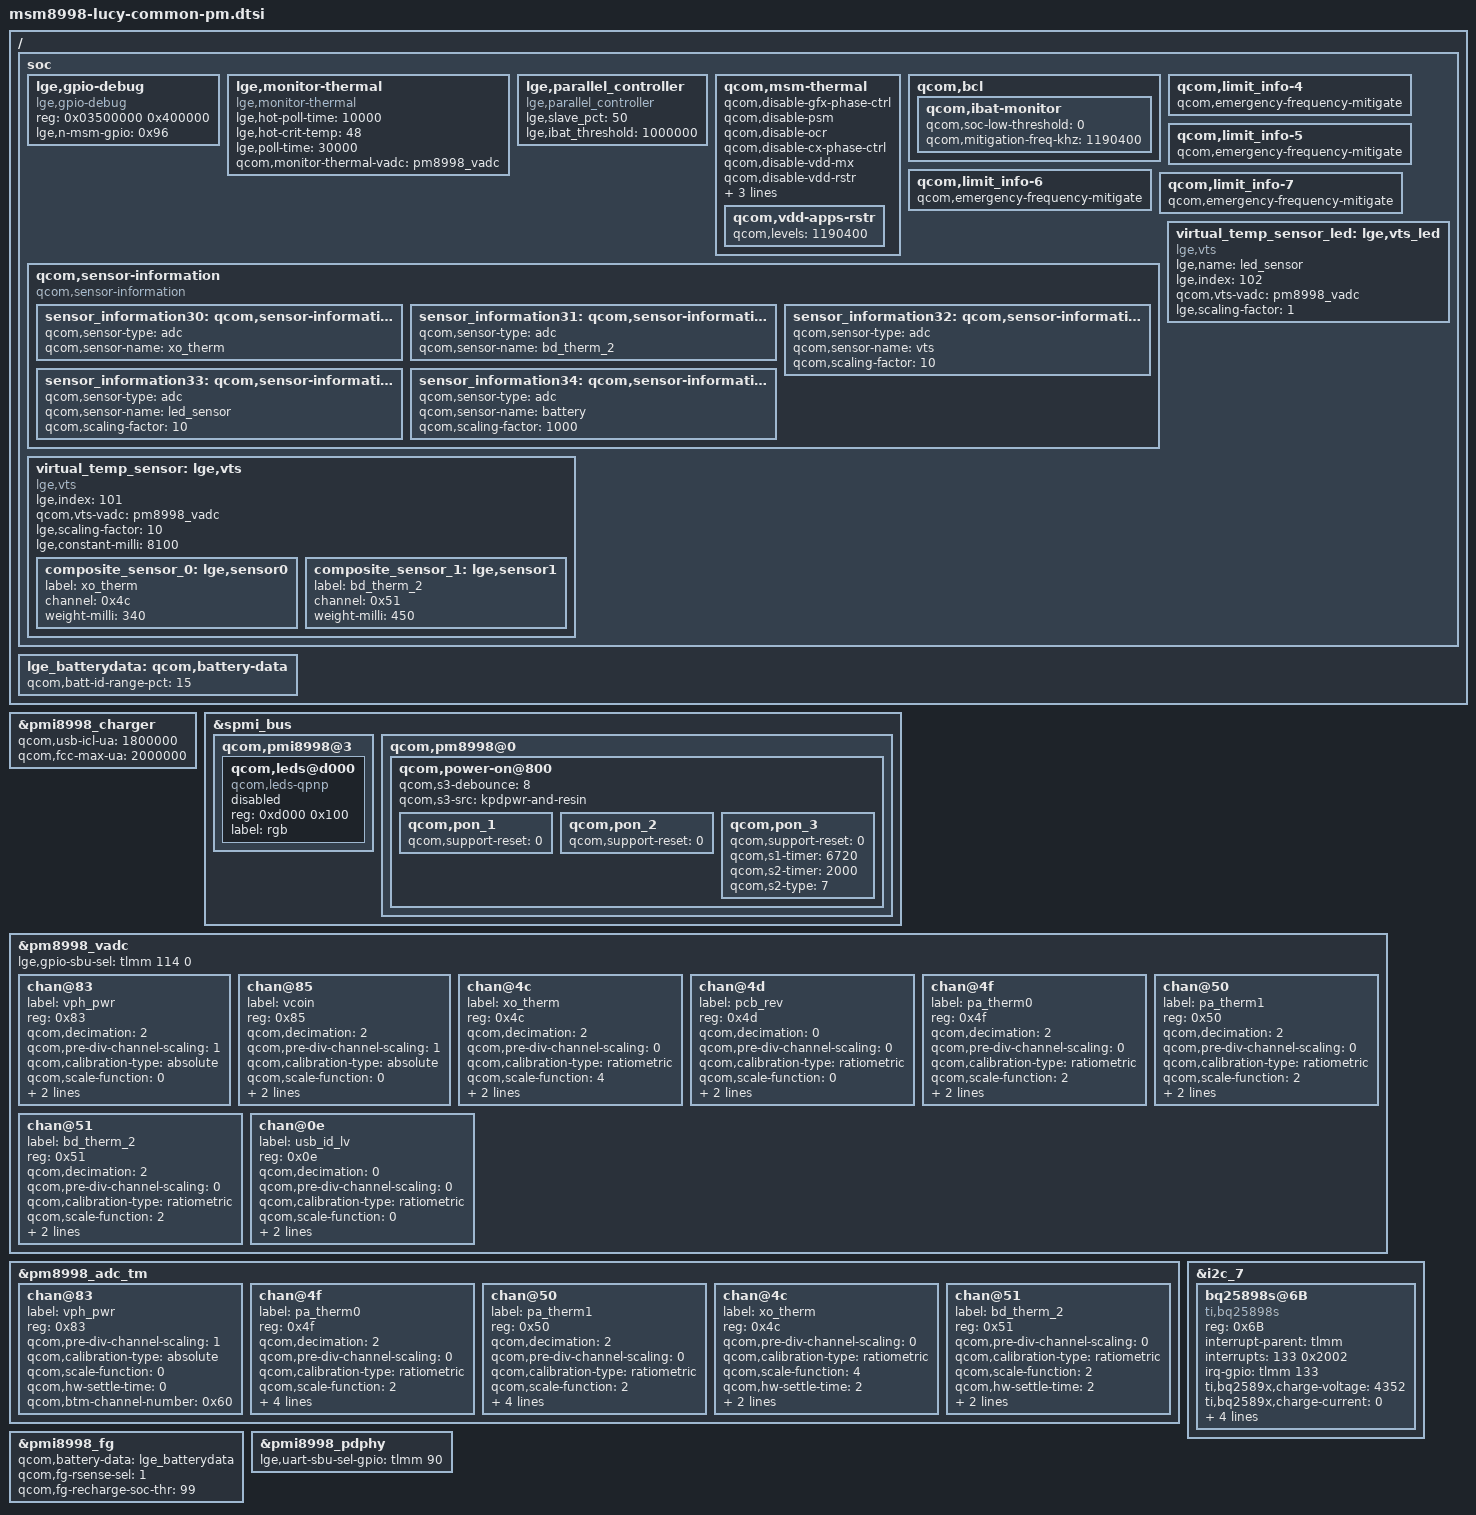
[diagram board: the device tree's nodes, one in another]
/* Copyright (c) 2014, The Linux Foundation. All rights reserved.
 *
 * This program is free software; you can redistribute it and/or modify
 * it under the terms of the GNU General Public License version 2 and
 * only version 2 as published by the Free Software Foundation.
 *
 * This program is distributed in the hope that it will be useful,
 * but WITHOUT ANY WARRANTY; without even the implied warranty of
 * MERCHANTABILITY or FITNESS FOR A PARTICULAR PURPOSE.  See the
 * GNU General Public License for more details.
 */

/ {
	soc {
		lge,gpio-debug {
			compatible = "lge,gpio-debug";
			reg = <0x03500000 0x400000>;
			reg-names = "tlmm-base";
			lge,n-msm-gpio = <0x96>;  /* MSM8996 GPIO 0 to 149 */
		};

		lge,monitor-thermal {
			compatible = "lge,monitor-thermal";
			status = "ok";
			lge,hot-poll-time = <10000>;
			lge,hot-crit-temp = <48>;
			lge,poll-time = <30000>;
			qcom,monitor-thermal-vadc = <&pm8998_vadc>;
		};

		lge,parallel_controller {
			compatible = "lge,parallel_controller";
			status = "ok";
			lge,slave_pct= <50>;
			lge,ibat_threshold = <1000000>;
		};

		qcom,msm-thermal {
			qcom,disable-gfx-phase-ctrl;
			qcom,disable-psm;
			qcom,disable-ocr;
			qcom,disable-cx-phase-ctrl;
			qcom,disable-vdd-mx;
			qcom,disable-vdd-rstr;
			/* mitigate gold cluster freq to 1.536Ghz */
			qcom,freq-mitigation-temp = <95>;
			qcom,freq-mitigation-temp-hysteresis = <10>;
			qcom,freq-mitigation-value = <1536000>;
			qcom,vdd-apps-rstr {
				qcom,levels = <1190400>;
			};
		};

		qcom,bcl {
			/delete-property/ qcom,bcl-soc-hotplug-list;
			qcom,ibat-monitor {
				qcom,soc-low-threshold = <0>;
				qcom,mitigation-freq-khz = <1190400>;
			};
		};

		qcom,limit_info-4 {
			qcom,emergency-frequency-mitigate;
		};

		qcom,limit_info-5 {
			qcom,emergency-frequency-mitigate;
		};

		qcom,limit_info-6 {
			qcom,emergency-frequency-mitigate;
		};

		qcom,limit_info-7 {
			qcom,emergency-frequency-mitigate;
		};

		qcom,sensor-information {
			compatible = "qcom,sensor-information";

			sensor_information30: qcom,sensor-information-30 {
				qcom,sensor-type = "adc";
				qcom,sensor-name = "xo_therm";
			};

			sensor_information31: qcom,sensor-information-31 {
				qcom,sensor-type = "adc";
				qcom,sensor-name = "bd_therm_2";
			};

			sensor_information32: qcom,sensor-information-32 {
				qcom,sensor-type = "adc";
				qcom,sensor-name = "vts";
				qcom,scaling-factor = <10>;
			};

			sensor_information33: qcom,sensor-information-33 {
				qcom,sensor-type = "adc";
				qcom,sensor-name = "led_sensor";
				qcom,scaling-factor = <10>;
			};

			sensor_information34: qcom,sensor-information-34 {
				qcom,sensor-type = "adc";
				qcom,sensor-name = "battery";
				qcom,scaling-factor = <1000>;
			};
		};

		/* TODO : tune, vts, 0.34*XO + 0.45*Bd2 + WLED/1000 + 8.1 */
		virtual_temp_sensor: lge,vts {
			compatible = "lge,vts";
			lge,index = <101>;
			qcom,vts-vadc = <&pm8998_vadc>;
			lge,scaling-factor = <10>;
			lge,constant-milli = <8100>;

			composite_sensor_0: lge,sensor0 {
				label = "xo_therm";
				channel = <0x4c>;
				weight-milli = <340>;
			};

			composite_sensor_1: lge,sensor1 {
				label = "bd_therm_2";
				channel = <0x51>;
				weight-milli = <450>;
			};
		};

		virtual_temp_sensor_led: lge,vts_led {
			compatible = "lge,vts";
			lge,name = "led_sensor";
			lge,index = <102>;
			qcom,vts-vadc = <&pm8998_vadc>;
			lge,scaling-factor= <1>;
		};
	};
};

&pmi8998_charger {
	qcom,usb-icl-ua = <1800000>;
	qcom,fcc-max-ua = <2000000>;
};

&spmi_bus {
	qcom,pmi8998@3 {
		qcom,leds@d000 {
			compatible = "qcom,leds-qpnp";
			reg = <0xd000 0x100>;
			label = "rgb";
			status = "disabled";
		};
	};
};

&pm8998_vadc {
	lge,gpio-sbu-sel = <&tlmm 114 0>;
	chan@83 {
		label = "vph_pwr";
		reg = <0x83>;
		qcom,decimation = <2>;
		qcom,pre-div-channel-scaling = <1>;
		qcom,calibration-type = "absolute";
		qcom,scale-function = <0>;
		qcom,hw-settle-time = <0>;
		qcom,fast-avg-setup = <0>;
	};

	chan@85 {
		label = "vcoin";
		reg = <0x85>;
		qcom,decimation = <2>;
		qcom,pre-div-channel-scaling = <1>;
		qcom,calibration-type = "absolute";
		qcom,scale-function = <0>;
		qcom,hw-settle-time = <0>;
		qcom,fast-avg-setup = <0>;
	};

	chan@4c {
		label = "xo_therm";
		reg = <0x4c>;
		qcom,decimation = <2>;
		qcom,pre-div-channel-scaling = <0>;
		qcom,calibration-type = "ratiometric";
		qcom,scale-function = <4>;
		qcom,hw-settle-time = <2>;
		qcom,fast-avg-setup = <0>;
	};

	chan@4d {
		label = "pcb_rev";
		reg = <0x4d>;
		qcom,decimation = <0>;
		qcom,pre-div-channel-scaling = <0>;
		qcom,calibration-type = "ratiometric";
		qcom,scale-function = <0>;
		qcom,hw-settle-time = <1>;
		qcom,fast-avg-setup = <0>;
	};

	chan@4f {
		label = "pa_therm0";
		reg = <0x4f>;
		qcom,decimation = <2>;
		qcom,pre-div-channel-scaling = <0>;
		qcom,calibration-type = "ratiometric";
		qcom,scale-function = <2>;
		qcom,hw-settle-time = <2>;
		qcom,fast-avg-setup = <0>;
	};

	chan@50 {
		label = "pa_therm1";
		reg = <0x50>;
		qcom,decimation = <2>;
		qcom,pre-div-channel-scaling = <0>;
		qcom,calibration-type = "ratiometric";
		qcom,scale-function = <2>;
		qcom,hw-settle-time = <2>;
		qcom,fast-avg-setup = <0>;
	};

	chan@51 {
		label = "bd_therm_2";
		reg = <0x51>;
		qcom,decimation = <2>;
		qcom,pre-div-channel-scaling = <0>;
		qcom,calibration-type = "ratiometric";
		qcom,scale-function = <2>;
		qcom,hw-settle-time = <2>;
		qcom,fast-avg-setup = <0>;
	};

	chan@0e {
		label = "usb_id_lv";
		reg = <0x0e>;
		qcom,decimation = <0>;
		qcom,pre-div-channel-scaling = <0>;
		qcom,calibration-type = "ratiometric";
		qcom,scale-function = <0>;
		qcom,hw-settle-time = <5>;
		qcom,fast-avg-setup = <0>;
	};
};

&pm8998_adc_tm {
	chan@83 {
		label = "vph_pwr";
		reg = <0x83>;
		qcom,pre-div-channel-scaling = <1>;
		qcom,calibration-type = "absolute";
		qcom,scale-function = <0>;
		qcom,hw-settle-time = <0>;
		qcom,btm-channel-number = <0x60>;
	};

	chan@4f {
		label = "pa_therm0";
		reg = <0x4f>;
		qcom,decimation = <2>;
		qcom,pre-div-channel-scaling = <0>;
		qcom,calibration-type = "ratiometric";
		qcom,scale-function = <2>;
		qcom,hw-settle-time = <2>;
		qcom,fast-avg-setup = <0>;
		qcom,btm-channel-number = <0x68>;
		qcom,thermal-node;
	};

	chan@50 {
		label = "pa_therm1";
		reg = <0x50>;
		qcom,decimation = <2>;
		qcom,pre-div-channel-scaling = <0>;
		qcom,calibration-type = "ratiometric";
		qcom,scale-function = <2>;
		qcom,hw-settle-time = <2>;
		qcom,fast-avg-setup = <0>;
		qcom,btm-channel-number = <0x70>;
		qcom,thermal-node;
	};

	chan@4c {
		label = "xo_therm";
		reg = <0x4c>;
		qcom,pre-div-channel-scaling = <0>;
		qcom,calibration-type = "ratiometric";
		qcom,scale-function = <4>;
		qcom,hw-settle-time = <2>;
		qcom,btm-channel-number = <0x78>;
		qcom,thermal-node;
	};

	chan@51 {
		label = "bd_therm_2";
		reg = <0x51>;
		qcom,pre-div-channel-scaling = <0>;
		qcom,calibration-type = "ratiometric";
		qcom,scale-function = <2>;
		qcom,hw-settle-time = <2>;
		qcom,btm-channel-number = <0x80>;
		qcom,thermal-node;
	};

};

&i2c_7 {
	status = "okay";
        bq25898s@6B{
            compatible = "ti,bq25898s";
            reg = <0x6B>;
            interrupt-parent = <&tlmm>;
            interrupts = <133 0x2002>;
            irq-gpio = <&tlmm 133 0x2002>;
            /delete-property/ti,bq2589x,enable-auto-dpdm;
            /delete-property/ti,bq2589x,enable-termination;
            /delete-property/ti,bq2589x,use-absolute-vindpm;
            ti,bq2589x,charge-voltage = <4352>;
            ti,bq2589x,charge-current = <0>;
            ti,bq2589x,term-current = <256>;
            ti,bq2589x,input-current-limit = <100>;
            ti,bq2589x,input-voltage-limit = <4400>;
            ti,bq2589x,watchdog-time = <0>;
        };
};

/{
	lge_batterydata: qcom,battery-data {
		qcom,batt-id-range-pct = <15>;
		#include "../../LGE_BLT32_LGC_3300mAh.dtsi"
		#include "../../LGE_BLT32_Tocad_3300mAh.dtsi"
	};
};

&pmi8998_fg {
	qcom,battery-data = <&lge_batterydata>;
	qcom,fg-rsense-sel = <1>;
	qcom,fg-recharge-soc-thr = <99>;
};

&pmi8998_pdphy {
	lge,uart-sbu-sel-gpio = <&tlmm 90 0>;
};

&spmi_bus {
		qcom,pm8998@0 {
			qcom,power-on@800 {
					qcom,s3-debounce = <8>;
					qcom,s3-src = "kpdpwr-and-resin";
					qcom,pon_1 {  /* KPD_PWR_N */
					status = "ok";
					qcom,support-reset = <0>;
					};
					qcom,pon_2 {  /* RESIN_N */
					status = "ok";
					qcom,support-reset = <0>;
					};
					qcom,pon_3 {  /* KPD_PWR_N AND RESIN_N */
					status = "ok";
					qcom,support-reset = <0>;
					qcom,s1-timer = <6720>;
					qcom,s2-timer = <2000>;
					qcom,s2-type = <7>;
					};
			};
		};
};
